AUTOSAR XML (schema 00048)
package /myproject/Application/Executable
  executable IAMApp03Exe: category=APPLICATION_LEVEL, build-type=BUILD-TYPE-DEBUG, logging-behavior=USES-LOGGING, reporting-behavior=REPORTS-EXECUTION-STATE
    root sw component prototype RootSwComponent: application-type=IAMApp03
package /myproject/Application/Process
  process IAMApp03_process: design=IAMApp03_processDesign, executable=IAMApp03Exe, log-trace-default-log-level=DEBUG, log-trace-file-path=/adar/install/var/log_apps/ECU1/IAMApp03, log-trace-log-modes=[CONSOLE, FILE, NETWORK], log-trace-process-desc=IAMApp03, log-trace-process-id=IAM3, state-dependent-startup-config{function-group-state=MachineState.Driving, startup-config=startup_config}
    process state machine ProcessStateMachine: type=ProcessState
package /myproject/Application/ProcessDesign
  process design IAMApp03_processDesign: executable=IAMApp03Exe
package /myproject/Application/SwComponent
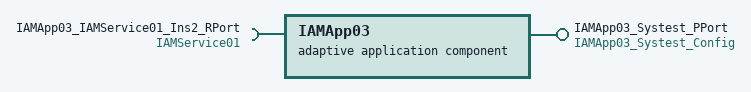
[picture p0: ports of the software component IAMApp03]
  adaptive application sw component type IAMApp03
    require port IAMApp03_IAMService01_Ins2_RPort: required-interface=IAMService01
      required-com-specs:
        queued-receiver-com-spec={data-element=Event01, receiver-capability=WILL-RECEIVE}
        client-com-spec={client-capability=WILL-CALL, operation=Method01}
        client-com-spec={client-capability=WILL-CALL, getter=Field01, setter=Field01}
        queued-receiver-com-spec={data-element=Field01, receiver-capability=WILL-RECEIVE}
    provide port IAMApp03_Systest_PPort: provided-interface=IAMApp03_Systest_Config
package /myproject/Service
  someip sd client event group timing config client_timingConf_1: request-response-delay={max-value=0.5, min-value=0.0}, subscribe-eventgroup-retry-delay=10.0, subscribe-eventgroup-retry-max=10, time-to-live=10
package /myproject/Service/IAMService01
  someip service instance to machine mapping IAMApp03_IAMService01_Ins2_RequiredServiceInstance_toMachine: communication-connector=ECU1CommunicationConnector, service-instance=IAMApp03_IAMService01_Required_Instance, udp-port=253
  service instance to port prototype mapping IAMApp03_IAMService01_Ins2_RequiredServiceInstance_toPort: port-prototype=IAMApp03_IAMService01_Ins2_RPort, process=IAMApp03_processDesign, service-instance=IAMApp03_IAMService01_Required_Instance
  required someip service instance IAMApp03_IAMService01_Required_Instance: service-interface-deployment=IAMService01_Dep, method-request-propss=[Someip_Method01Dep, Someip_Field01Dep_Getter, Someip_Field01Dep_Setter], required-minor-version=0, required-service-instance-id=2, version-driven-find-behavior=MINIMUM-MINOR-VERSION
    someip required event group SomeipREventGroup_1: event-group=EventGroup_1, sd-client-event-group-timing-config=client_timingConf_1
    someip required event group SomeipREventGroup_2: event-group=EventGroup_2, sd-client-event-group-timing-config=client_timingConf_1
package /myproject/Service/Systest
  someip service instance to machine mapping IAMApp03_Systest_ProvidedServiceInstance_toMachine: communication-connector=ECU1CommunicationConnector, service-instance=IAMApp03_Systest_Provided_Instance, udp-port=31403
  service instance to port prototype mapping IAMApp03_Systest_ProvidedServiceInstance_toPort: port-prototype=IAMApp03_Systest_PPort, process=IAMApp03_processDesign, service-instance=IAMApp03_Systest_Provided_Instance
  provided someip service instance IAMApp03_Systest_Provided_Instance: service-interface-deployment=IAMApp03_Systest_Config_Dep, service-instance-id=3
    method-response-propss:
      Someip_CallService01Ins02Method01Dep
      Someip_GetterService01Ins02Field01NotifierDep
      Someip_SetterService01Ins02Field01NotifierDep
      Someip_StartFindServiceDep
      Someip_StopFindServiceDep
      Someip_SubcribeService01Ins02Event01Dep
      Someip_SubcribeService01Ins02Field01NotifierDep
      Someip_UnsubcribeService01Ins02Event01Dep
      Someip_UnsubcribeService01Ins02Field01NotifierDep
package /myproject/System/ProcessToMachineMappingSet
  process to machine mapping set IAMApp03procToMachineMappingSet
    process to machine mapping procToMachineMapping: machine=ECU1Machine, process=IAMApp03_process
package /myproject/System/StartupConfigSet
  startup config set IAMApp03_startup_set
    startup config startup_config: scheduling-policy=SCHEDULING-POLICY-ROUND-ROBIN, scheduling-priority=12, timeout={enter-timeout-value=3.0, exit-timeout-value=3.0}
